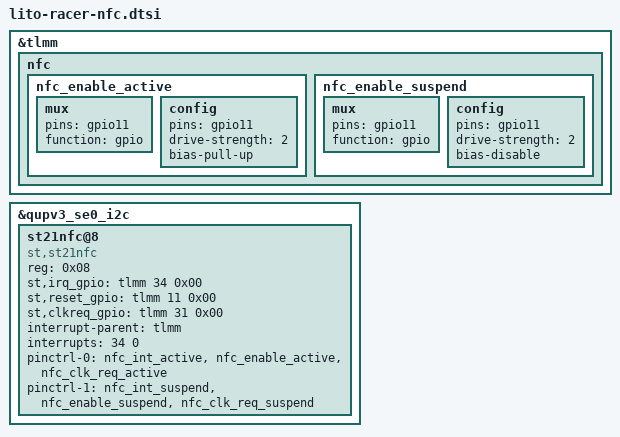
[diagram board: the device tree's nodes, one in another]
&tlmm {
	nfc {
		nfc_enable_active: nfc_enable_active {
			/* active state */
			mux {
				/* 11: Enable */
				pins = "gpio11";
				function = "gpio";
			};

			config {
				pins = "gpio11";
				drive-strength = <2>; /* 2 MA */
				bias-pull-up;
			};
		};

		nfc_enable_suspend: nfc_enable_suspend {
			/* sleep state */
			mux {
				/* 11: Enable */
				pins = "gpio11";
				function = "gpio";
			};

			config {
				pins = "gpio11";
				drive-strength = <2>; /* 2 MA */
				bias-disable;
			};
		};
	};

};

&qupv3_se0_i2c {
	status = "ok";
	st21nfc@8 {
		compatible = "st,st21nfc";
		status = "ok";
		reg = <0x08>;
		st,irq_gpio = <&tlmm 34 0x00>;
		st,reset_gpio = <&tlmm 11 0x00>;
		st,clkreq_gpio = <&tlmm 31 0x00>;
		interrupt-parent = <&tlmm>;
		interrupts = <34 0>;
		interrupt-names = "nfc_irq";
		pinctrl-names = "nfc_active", "nfc_suspend";
		pinctrl-0 = <&nfc_int_active &nfc_enable_active
				&nfc_clk_req_active>;
		pinctrl-1 = <&nfc_int_suspend &nfc_enable_suspend
				&nfc_clk_req_suspend>;
	};
};

